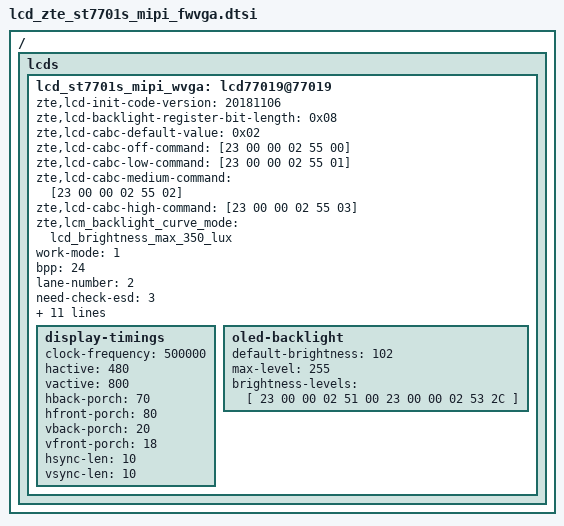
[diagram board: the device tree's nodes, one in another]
/ { lcds {
	lcd_st7701s_mipi_wvga: lcd77019@77019 {
		zte,lcd-init-code-version = "20181106";
		zte,lcd-backlight-register-bit-length = <0x08>;
		zte,lcd-cabc-default-value = <0x02>;
		zte,lcd-cabc-off-command = [23 00 00 02 55 00];
		zte,lcd-cabc-low-command = [23 00 00 02 55 01];
		zte,lcd-cabc-medium-command = [23 00 00 02 55 02];
		zte,lcd-cabc-high-command = [23 00 00 02 55 03];
		zte,lcm_backlight_curve_mode = "lcd_brightness_max_350_lux";

		work-mode = <1>;
		bpp = <24>;
		lane-number = <2>;

		need-check-esd = <3>;
		esd-timeout = <2000>;

		fps = <60>;
		width-mm = <55>;
		height-mm = <94>;
		panel-name = "lcd_st7701s_mipi_wvga";

		power-on-sequence = <
					32  1  10
					32  0  20
					32  1  120
					>;
		power-off-sequence = <
					32  0  20
					>;

		init-data = [
			39 00 00 06 FF 77 01 00 00 13
			39 00 00 02 EF 08
			39 00 00 03 E8 00 0E
			39 0A 00 03 E8 00 0C
			39 00 00 03 E8 00 00

			39 00 00 06 FF 77 01 00 00 10
			39 00 00 03 C0 63 00
			39 00 00 03 C1 0B 02
			39 00 00 03 C2 01 07
			39 00 00 02 CC 10
			39 00 00 11 B0 00 07 14 14 19 0B 11 08 08 27 07 15 11 16 1A DD
			39 00 00 11 B1 00 07 15 14 19 0B 15 0A 09 26 07 15 11 18 1A DD
			39 00 00 06 FF 77 01 00 00 11
			39 00 00 02 B0 5F
			39 00 00 02 B1 66
			39 00 00 02 B2 85
			39 00 00 02 B3 80
			39 00 00 02 B5 45
			39 00 00 02 B7 85
			39 00 00 02 B8 20
			39 00 00 02 B9 10
			39 00 00 02 BA 00
			39 00 00 02 BC 00
			39 00 00 02 C1 08
			39 00 00 02 C2 08
			39 00 00 02 D0 88
			39 00 00 04 E0 00 00 02
			39 00 00 0C E1 04 A0 00 00 05 A0 00 00 00 20 20
			39 00 00 0E E2 00 00 00 00 00 00 00 00 00 00 00 00 00
			39 00 00 05 E3 00 00 33 00
			39 00 00 03 E4 22 00
			39 00 00 11 E5 03 34 A0 A0 05 34 A0 A0 00 00 00 00 00 00 00 00
			39 00 00 05 E6 00 00 33 00
			39 00 00 03 E7 22 00
			39 00 00 11 E8 04 34 A0 A0 06 34 A0 A0 00 00 00 00 00 00 00 00
			39 00 00 08 EB 02 00 40 40 00 00 00
			39 00 00 03 EC 00 00
			39 00 00 11 ED FA 45 0B FF FF FF FF FF FF FF FF FF FF B0 54 AF
			39 00 00 06 FF 77 01 00 00 00
			39 00 00 06 FF 77 01 00 00 10
			39 00 00 02 CC 10
			39 00 00 02 CA 11
			39 00 00 02 BC 01
			39 00 00 02 BB 00
			39 00 00 06 FF 77 01 00 00 00
			39 00 00 02 35 00
			39 00 00 02 51 00
			39 00 00 02 53 0C
			39 00 00 02 55 02
			23 78 00 02 11 00
			23 0a 00 02 29 00
			];
		sleep-in = [
			13 0A 00 01 28
			13 78 00 01 10
			];
		sleep-out = [
			13 78 00 01 11
			13 0a 00 01 29
			];

		display-timings {
			clock-frequency = <500000>;
			hactive = <480>;
			vactive = <800>;
			hback-porch = <70>;
			hfront-porch = <80>;
			vback-porch = <20>;
			vfront-porch = <18>;
			hsync-len = <10>;
			vsync-len = <10>;
		};
		oled-backlight {
			default-brightness = <102>;
			max-level = <255>;
			brightness-levels = [
				23 00 00 02 51 00
				23 00 00 02 53 2C
			];
		};
	};
};};

